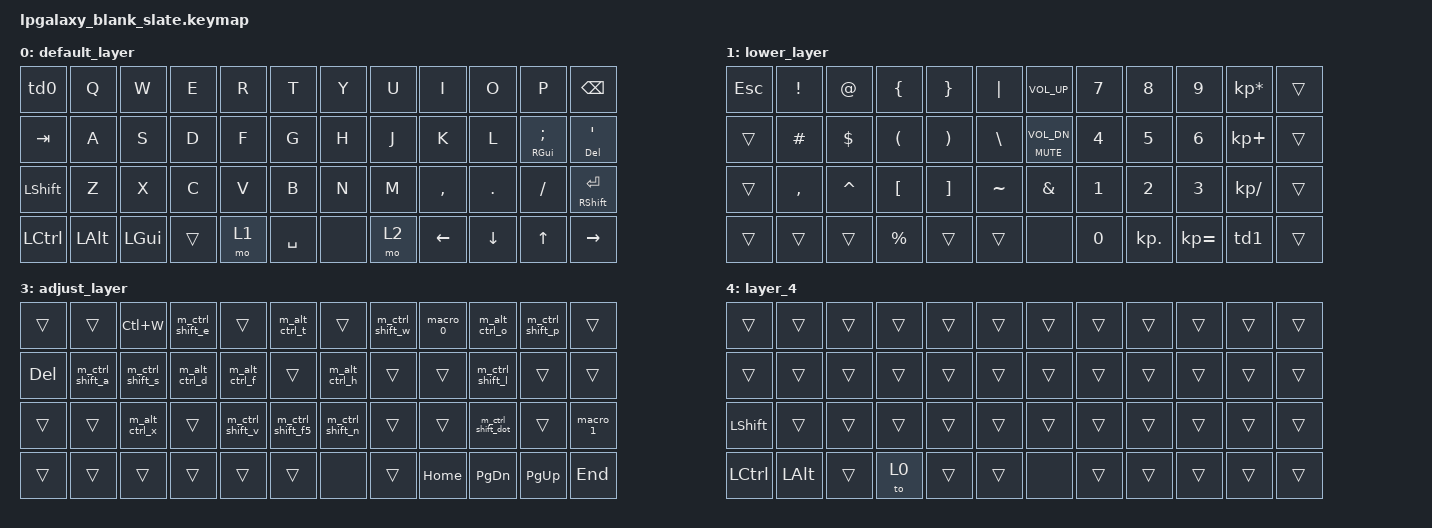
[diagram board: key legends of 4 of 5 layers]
/*
 * Copyright (c) 2020 The ZMK Contributors
 * SPDX-License-Identifier: MIT
 */

#include <behaviors.dtsi>
#include <dt-bindings/zmk/keys.h>

/ {
    macros {
        macro_0: macro_0 {
            compatible = "zmk,behavior-macro";
            #binding-cells = <0>;
            bindings
                = <&macro_press &kp LCTRL>
                , <&macro_tap &kp I>
                , <&macro_release &kp LCTRL>
                , <&macro_wait_time 100>
                , <&macro_tap &kp I>
                , <&macro_wait_time 100>
                , <&macro_tap &kp D>
                , <&macro_wait_time 100>
                , <&macro_press &kp LCTRL>
                , <&macro_tap &kp I>
                , <&macro_release &kp LCTRL>
                , <&macro_wait_time 100>
                , <&macro_tap &kp DOT>;
        };
        macro_1: macro_1 {
            compatible = "zmk,behavior-macro";
            #binding-cells = <0>;
            bindings
                = <&macro_press &kp LCTRL>
                , <&macro_tap &kp SQT>
                , <&macro_release &kp LCTRL>
                , <&macro_wait_time 100>
                , <&macro_press &kp LCTRL>
                , <&macro_tap &kp SQT>
                , <&macro_release &kp LCTRL>;
        };

        // Layer 3 (Adjust) Macros - VS Code shortcuts
        m_ctrl_shift_e: m_ctrl_shift_e {
            compatible = "zmk,behavior-macro";
            #binding-cells = <0>;
            bindings = <&macro_press &kp LCTRL &kp LSHIFT>
                     , <&macro_tap &kp E>
                     , <&macro_release &kp LCTRL &kp LSHIFT>;
        };
        m_alt_ctrl_t: m_alt_ctrl_t {
            compatible = "zmk,behavior-macro";
            #binding-cells = <0>;
            bindings = <&macro_press &kp LALT &kp LCTRL>
                     , <&macro_tap &kp T>
                     , <&macro_release &kp LALT &kp LCTRL>;
        };
        m_ctrl_shift_w: m_ctrl_shift_w {
            compatible = "zmk,behavior-macro";
            #binding-cells = <0>;
            bindings = <&macro_press &kp LCTRL &kp LSHIFT>
                     , <&macro_tap &kp W>
                     , <&macro_release &kp LCTRL &kp LSHIFT>;
        };
        m_alt_ctrl_o: m_alt_ctrl_o {
            compatible = "zmk,behavior-macro";
            #binding-cells = <0>;
            bindings = <&macro_press &kp LALT &kp LCTRL>
                     , <&macro_tap &kp O>
                     , <&macro_release &kp LALT &kp LCTRL>;
        };
        m_ctrl_shift_p: m_ctrl_shift_p {
            compatible = "zmk,behavior-macro";
            #binding-cells = <0>;
            bindings = <&macro_press &kp LCTRL &kp LSHIFT>
                     , <&macro_tap &kp P>
                     , <&macro_release &kp LCTRL &kp LSHIFT>;
        };
        m_ctrl_shift_a: m_ctrl_shift_a {
            compatible = "zmk,behavior-macro";
            #binding-cells = <0>;
            bindings = <&macro_press &kp LCTRL &kp LSHIFT>
                     , <&macro_tap &kp A>
                     , <&macro_release &kp LCTRL &kp LSHIFT>;
        };
        m_ctrl_shift_s: m_ctrl_shift_s {
            compatible = "zmk,behavior-macro";
            #binding-cells = <0>;
            bindings = <&macro_press &kp LCTRL &kp LSHIFT>
                     , <&macro_tap &kp S>
                     , <&macro_release &kp LCTRL &kp LSHIFT>;
        };
        m_alt_ctrl_d: m_alt_ctrl_d {
            compatible = "zmk,behavior-macro";
            #binding-cells = <0>;
            bindings = <&macro_press &kp LALT &kp LCTRL>
                     , <&macro_tap &kp D>
                     , <&macro_release &kp LALT &kp LCTRL>;
        };
        m_alt_ctrl_f: m_alt_ctrl_f {
            compatible = "zmk,behavior-macro";
            #binding-cells = <0>;
            bindings = <&macro_press &kp LALT &kp LCTRL>
                     , <&macro_tap &kp F>
                     , <&macro_release &kp LALT &kp LCTRL>;
        };
        m_alt_ctrl_h: m_alt_ctrl_h {
            compatible = "zmk,behavior-macro";
            #binding-cells = <0>;
            bindings = <&macro_press &kp LALT &kp LCTRL>
                     , <&macro_tap &kp H>
                     , <&macro_release &kp LALT &kp LCTRL>;
        };
        m_ctrl_shift_l: m_ctrl_shift_l {
            compatible = "zmk,behavior-macro";
            #binding-cells = <0>;
            bindings = <&macro_press &kp LCTRL &kp LSHIFT>
                     , <&macro_tap &kp L>
                     , <&macro_release &kp LCTRL &kp LSHIFT>;
        };
        m_alt_ctrl_x: m_alt_ctrl_x {
            compatible = "zmk,behavior-macro";
            #binding-cells = <0>;
            bindings = <&macro_press &kp LALT &kp LCTRL>
                     , <&macro_tap &kp X>
                     , <&macro_release &kp LALT &kp LCTRL>;
        };
        m_ctrl_shift_v: m_ctrl_shift_v {
            compatible = "zmk,behavior-macro";
            #binding-cells = <0>;
            bindings = <&macro_press &kp LCTRL &kp LSHIFT>
                     , <&macro_tap &kp V>
                     , <&macro_release &kp LCTRL &kp LSHIFT>;
        };
        m_ctrl_shift_f5: m_ctrl_shift_f5 {
            compatible = "zmk,behavior-macro";
            #binding-cells = <0>;
            bindings = <&macro_press &kp LCTRL &kp LSHIFT>
                     , <&macro_tap &kp F5>
                     , <&macro_release &kp LCTRL &kp LSHIFT>;
        };
        m_ctrl_shift_n: m_ctrl_shift_n {
            compatible = "zmk,behavior-macro";
            #binding-cells = <0>;
            bindings = <&macro_press &kp LCTRL &kp LSHIFT>
                     , <&macro_tap &kp N>
                     , <&macro_release &kp LCTRL &kp LSHIFT>;
        };
        m_ctrl_shift_dot: m_ctrl_shift_dot {
            compatible = "zmk,behavior-macro";
            #binding-cells = <0>;
            bindings = <&macro_press &kp LCTRL &kp LSHIFT>
                     , <&macro_tap &kp DOT>
                     , <&macro_release &kp LCTRL &kp LSHIFT>;
        };
    };

    behaviors {
        td0: tap_dance_0 {
            compatible = "zmk,behavior-tap-dance";
            #binding-cells = <0>;
            tapping-term-ms = <200>;
            bindings = <&kp ESC>, <&kp TAB>;
        };
        td1: tap_dance_1 {
            compatible = "zmk,behavior-tap-dance";
            #binding-cells = <0>;
            tapping-term-ms = <200>;
            bindings = <&kp MINUS>, <&kp EQUAL>;
        };
    
        ht_balanced: hold_tap_balanced {
            compatible = "zmk,behavior-hold-tap";
            #binding-cells = <2>;
            flavor = "balanced";
            tapping-term-ms = <280>;           // ← Change this to 300
            quick-tap-ms = <175>;              // ← Change this to 200
            require-prior-idle-ms = <150>;     // ← Change this to 125
            bindings = <&kp>, <&kp>;
        };
    };

    combos {
        compatible = "zmk,combos";
        combo_studio_unlock {
            timeout-ms = <50>;
            key-positions = <0 11>;
            bindings = <&studio_unlock>;
        };
    };

    keymap {
        compatible = "zmk,keymap";

        default_layer {
            bindings = <
                &td0 &kp Q &kp W &kp E &kp R &kp T &kp Y &kp U &kp I &kp O &kp P &kp BSPC
                &kp TAB &kp A &kp S &kp D &kp F &kp G &kp H &kp J &kp K &kp L &ht_balanced RIGHT_GUI SEMICOLON &ht_balanced DEL SQT
                &kp LEFT_SHIFT &kp Z &kp X &kp C &kp V &kp B &kp N &kp M &kp COMMA &kp DOT &kp SLASH &ht_balanced RIGHT_SHIFT ENTER
                &kp LEFT_CONTROL &kp LEFT_ALT &kp LEFT_GUI &trans &mo 1 &kp SPACE &none &mo 2 &kp LEFT &kp DOWN &kp UP &kp RIGHT
            >;
        };

        lower_layer {
            bindings = <
                &kp ESCAPE &kp EXCL &kp AT &kp LBRC &kp RBRC &kp PIPE &kp C_VOLUME_UP &kp N7 &kp N8 &kp N9 &kp KP_ASTERISK &trans
                &trans &kp HASH &kp DLLR &kp LPAR &kp RPAR &kp BACKSLASH &ht_balanced C_MUTE C_VOL_DN &kp N4 &kp N5 &kp N6 &kp KP_PLUS &trans
                &trans &kp COMMA &kp CARET &kp LEFT_BRACKET &kp RIGHT_BRACKET &kp TILDE &kp AMPS &kp N1 &kp N2 &kp N3 &kp KP_SLASH &trans
                &trans &trans &trans &kp PRCNT &trans &trans &none &kp N0 &kp KP_DOT &kp KP_EQUAL &td1 &trans
            >;
        };

        raise_layer {
            bindings = <
                &kp F1 &kp F2 &kp F3 &kp F4 &kp F5 &kp F6 &kp F7 &kp F8 &kp F9 &kp F10 &kp F11 &kp F12
                &trans &trans &trans &trans &trans &trans &trans &trans &trans &trans &trans &trans
                &trans &trans &trans &trans &trans &trans &trans &trans &trans &trans &trans &trans
                &trans &trans &to 4 &trans &trans &none &trans &kp HOME &kp PAGE_DOWN &kp PAGE_UP &kp END
            >;
        };

        adjust_layer {
            bindings = <
                &trans &trans &kp LC(W) &m_ctrl_shift_e &trans &m_alt_ctrl_t &trans &m_ctrl_shift_w &macro_0 &m_alt_ctrl_o &m_ctrl_shift_p &trans
                &kp DEL &m_ctrl_shift_a &m_ctrl_shift_s &m_alt_ctrl_d &m_alt_ctrl_f &trans &m_alt_ctrl_h &trans &trans &m_ctrl_shift_l &trans &trans
                &trans &trans &m_alt_ctrl_x &trans &m_ctrl_shift_v &m_ctrl_shift_f5 &m_ctrl_shift_n &trans &trans &m_ctrl_shift_dot &trans &macro_1
                &trans &trans &trans &trans &trans &trans &none &trans &kp HOME &kp PG_DN &kp PG_UP &kp END
            >;
        };

        layer_4 {
            bindings = <
                &trans &trans &trans &trans &trans &trans &trans &trans &trans &trans &trans &trans
                &trans &trans &trans &trans &trans &trans &trans &trans &trans &trans &trans &trans
                &kp LEFT_SHIFT &trans &trans &trans &trans &trans &trans &trans &trans &trans &trans &trans
                &kp LEFT_CONTROL &kp LEFT_ALT &trans &to 0 &trans &trans &none &trans &trans &trans &trans &trans
            >;
        };
    };
};
